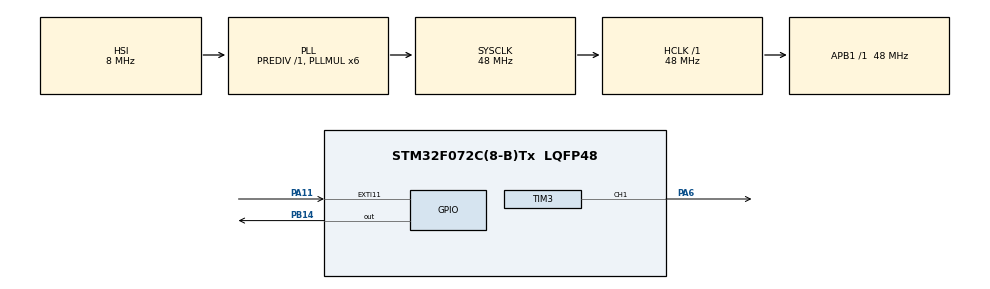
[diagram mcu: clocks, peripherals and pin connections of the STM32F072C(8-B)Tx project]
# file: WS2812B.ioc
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Dma.Request0=TIM3_CH1/TRIG
Dma.TIM3_CH1/TRIG.0.Direction=DMA_MEMORY_TO_PERIPH
Dma.TIM3_CH1/TRIG.0.Instance=DMA1_Channel4
Dma.TIM3_CH1/TRIG.0.MemDataAlignment=DMA_MDATAALIGN_BYTE
Dma.TIM3_CH1/TRIG.0.MemInc=DMA_MINC_ENABLE
Dma.TIM3_CH1/TRIG.0.Mode=DMA_NORMAL
Dma.TIM3_CH1/TRIG.0.PeriphDataAlignment=DMA_PDATAALIGN_BYTE
Dma.TIM3_CH1/TRIG.0.PeriphInc=DMA_PINC_DISABLE
Dma.TIM3_CH1/TRIG.0.Priority=DMA_PRIORITY_LOW
Mcu.Family=STM32F0
Mcu.Name=STM32F072C(8-B)Tx
Mcu.Package=LQFP48
NVIC.DMA1_Channel4_5_6_7_IRQn=true\:0\:0\:false\:false\:true\:false\:true
NVIC.EXTI4_15_IRQn=true\:0\:0\:false\:false\:true\:true\:true
PA11.GPIO_ModeDefaultEXTI=GPIO_MODE_IT_FALLING
PA11.GPIO_PuPd=GPIO_PULLUP
PA11.Signal=GPXTI11
PA13.Mode=Serial_Wire
PA13.Signal=SYS_SWDIO
PA14.Mode=Serial_Wire
PA14.Signal=SYS_SWCLK
PA6.Signal=S_TIM3_CH1
PB14.Signal=GPIO_Output
ProjectManager.HeapSize=0x200
ProjectManager.StackSize=0x400
ProjectManager.TargetToolchain=STM32CubeIDE
RCC.AHBFreq_Value=48000000
RCC.APB1Freq_Value=48000000
RCC.APB1TimFreq_Value=48000000
RCC.HCLKFreq_Value=48000000
RCC.HSE_VALUE=16000000
RCC.PLLMUL=RCC_PLL_MUL6
RCC.SYSCLKFreq_VALUE=48000000
RCC.SYSCLKSource=RCC_SYSCLKSOURCE_PLLCLK
SH.S_TIM3_CH1.0=TIM3_CH1,PWM Generation1 CH1
TIM3.Channel-PWM\ Generation1\ CH1=TIM_CHANNEL_1
TIM3.Period=59
board=custom

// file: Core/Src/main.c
/* USER CODE BEGIN Header */
/**
  ******************************************************************************
  * @file           : main.c
  * @brief          : Main program body
  ******************************************************************************
  * @attention
  *
  * <h2><center>&copy; Copyright (c) 2021 STMicroelectronics.
  * All rights reserved.</center></h2>
  *
  * This software component is licensed by ST under BSD 3-Clause license,
  * the "License"; You may not use this file except in compliance with the
  * License. You may obtain a copy of the License at:
  *                        opensource.org/licenses/BSD-3-Clause
  *
  ******************************************************************************
  */
/* USER CODE END Header */
#include "main.h"
#include "ws2812_LED.h"

TIM_HandleTypeDef htim3;
DMA_HandleTypeDef hdma_tim3_ch1_trig;

void SystemClock_Config(void);
static void MX_GPIO_Init(void);
static void MX_DMA_Init(void);
static void MX_TIM3_Init(void);

WS_INIT_(my,10,&htim3,TIM_CHANNEL_1)
int main(void)
{

  /* MCU Configuration--------------------------------------------------------*/

  /* Reset of all peripherals, Initializes the Flash interface and the Systick. */
  HAL_Init();

  /* Configure the system clock */
  SystemClock_Config();

  /* Initialize all configured peripherals */
  MX_GPIO_Init();
  MX_DMA_Init();
  MX_TIM3_Init();

  WS2812_Init(&my);

  /* Infinite loop */
  /* USER CODE BEGIN WHILE */
  while (1)
  {
	  WS2812_Clear_buf(&my);
	  WS2812_setColor_All_Pixel(&my,0,0,255);
	  WS2812_Update(&my);
	  HAL_Delay(300);

	  WS2812_Clear_buf(&my);
	  WS2812_setColor_All_Pixel(&my,0,255,0);
	  WS2812_Update(&my);
	  HAL_Delay(300);
    /* USER CODE END WHILE */

  }
}

void SystemClock_Config(void)
{
  RCC_OscInitTypeDef RCC_OscInitStruct = {0};
  RCC_ClkInitTypeDef RCC_ClkInitStruct = {0};

  /** Initializes the RCC Oscillators according to the specified parameters
  * in the RCC_OscInitTypeDef structure.
  */
  RCC_OscInitStruct.OscillatorType = RCC_OSCILLATORTYPE_HSI;
  RCC_OscInitStruct.HSIState = RCC_HSI_ON;
  RCC_OscInitStruct.HSICalibrationValue = RCC_HSICALIBRATION_DEFAULT;
  RCC_OscInitStruct.PLL.PLLState = RCC_PLL_ON;
  RCC_OscInitStruct.PLL.PLLSource = RCC_PLLSOURCE_HSI;
  RCC_OscInitStruct.PLL.PLLMUL = RCC_PLL_MUL6;
  RCC_OscInitStruct.PLL.PREDIV = RCC_PREDIV_DIV1;
  if (HAL_RCC_OscConfig(&RCC_OscInitStruct) != HAL_OK)
  {
    Error_Handler();
  }
  /** Initializes the CPU, AHB and APB buses clocks
  */
  RCC_ClkInitStruct.ClockType = RCC_CLOCKTYPE_HCLK|RCC_CLOCKTYPE_SYSCLK
                              |RCC_CLOCKTYPE_PCLK1;
  RCC_ClkInitStruct.SYSCLKSource = RCC_SYSCLKSOURCE_PLLCLK;
  RCC_ClkInitStruct.AHBCLKDivider = RCC_SYSCLK_DIV1;
  RCC_ClkInitStruct.APB1CLKDivider = RCC_HCLK_DIV1;

  if (HAL_RCC_ClockConfig(&RCC_ClkInitStruct, FLASH_LATENCY_1) != HAL_OK)
  {
    Error_Handler();
  }
}

static void MX_TIM3_Init(void)
{

  TIM_MasterConfigTypeDef sMasterConfig = {0};
  TIM_OC_InitTypeDef sConfigOC = {0};

  htim3.Instance = TIM3;
  htim3.Init.Prescaler = 0;
  htim3.Init.CounterMode = TIM_COUNTERMODE_UP;
  htim3.Init.Period = 59;
  htim3.Init.ClockDivision = TIM_CLOCKDIVISION_DIV1;
  htim3.Init.AutoReloadPreload = TIM_AUTORELOAD_PRELOAD_DISABLE;
  if (HAL_TIM_PWM_Init(&htim3) != HAL_OK)
  {
    Error_Handler();
  }
  sMasterConfig.MasterOutputTrigger = TIM_TRGO_RESET;
  sMasterConfig.MasterSlaveMode = TIM_MASTERSLAVEMODE_DISABLE;
  if (HAL_TIMEx_MasterConfigSynchronization(&htim3, &sMasterConfig) != HAL_OK)
  {
    Error_Handler();
  }
  sConfigOC.OCMode = TIM_OCMODE_PWM1;
  sConfigOC.Pulse = 0;
  sConfigOC.OCPolarity = TIM_OCPOLARITY_HIGH;
  sConfigOC.OCFastMode = TIM_OCFAST_DISABLE;
  if (HAL_TIM_PWM_ConfigChannel(&htim3, &sConfigOC, TIM_CHANNEL_1) != HAL_OK)
  {
    Error_Handler();
  }
  /* USER CODE BEGIN TIM3_Init 2 */
  /* Peripheral DMA init*/

  /* USER CODE END TIM3_Init 2 */
  HAL_TIM_MspPostInit(&htim3);

}

static void MX_DMA_Init(void)
{

  /* DMA controller clock enable */
  __HAL_RCC_DMA1_CLK_ENABLE();

  /* DMA interrupt init */
  /* DMA1_Channel4_5_6_7_IRQn interrupt configuration */
  HAL_NVIC_SetPriority(DMA1_Channel4_5_6_7_IRQn, 0, 0);
  HAL_NVIC_EnableIRQ(DMA1_Channel4_5_6_7_IRQn);

}

static void MX_GPIO_Init(void)
{
  GPIO_InitTypeDef GPIO_InitStruct = {0};

  /* GPIO Ports Clock Enable */
  __HAL_RCC_GPIOA_CLK_ENABLE();
  __HAL_RCC_GPIOB_CLK_ENABLE();

  /*Configure GPIO pin Output Level */
  HAL_GPIO_WritePin(GPIOB, GPIO_PIN_14, GPIO_PIN_RESET);

  /*Configure GPIO pin : PB14 */
  GPIO_InitStruct.Pin = GPIO_PIN_14;
  GPIO_InitStruct.Mode = GPIO_MODE_OUTPUT_PP;
  GPIO_InitStruct.Pull = GPIO_NOPULL;
  GPIO_InitStruct.Speed = GPIO_SPEED_FREQ_LOW;
  HAL_GPIO_Init(GPIOB, &GPIO_InitStruct);

  /*Configure GPIO pin : PA11 */
  GPIO_InitStruct.Pin = GPIO_PIN_11;
  GPIO_InitStruct.Mode = GPIO_MODE_IT_FALLING;
  GPIO_InitStruct.Pull = GPIO_PULLUP;
  HAL_GPIO_Init(GPIOA, &GPIO_InitStruct);

  /* EXTI interrupt init*/
  HAL_NVIC_SetPriority(EXTI4_15_IRQn, 0, 0);
  HAL_NVIC_EnableIRQ(EXTI4_15_IRQn);

}

void Error_Handler(void)
{
  __disable_irq();
  while (1)
  {
  }
}

/************************ (C) COPYRIGHT STMicroelectronics *****END OF FILE****/
